AUTOSAR XML (schema 00049)
package /DataType/Implementation/CPP
  25 x std cpp implementation data type:
    AppVersion: category=ARRAY, array-size=6, cpp-template-argument=uint8_t
      namespaces:
        symbol props data
        symbol props table
    Color_Index: category=ARRAY, array-size=3, cpp-template-argument=uint8_t
      namespaces:
        symbol props data
        symbol props table
    Complete_Time: category=ARRAY, array-size=2, cpp-template-argument=uint8_t
      namespaces:
        symbol props data
        symbol props table
    Date: category=ARRAY, array-size=8, cpp-template-argument=uint8_t
      namespaces:
        symbol props data
        symbol props table
    Elapsed_Time: category=ARRAY, array-size=2, cpp-template-argument=uint8_t
      namespaces:
        symbol props data
        symbol props table
    Finished_Time: category=ARRAY, array-size=7, cpp-template-argument=uint8_t
      namespaces:
        symbol props data
        symbol props table
    InputData: category=STRUCTURE
      namespaces:
        symbol props bms
        symbol props input
      26 x cpp implementation data type element, all with type-reference=uint32_t:
        InterfaceIDforDbg
        DataSerialNumber
        VehicleUniqueSnr
        EMS_BatteryAvgTemperature
        EMS_ChargerOutputVolt
        EMS_ChargerOutputCurr
        EMS_ReturnCode
        EMS_ConnectionStatus
        EMS_TargetVolt
        EMS_TargetCurr
        EMS_RemainHour
        EMS_RemainMin
        EMS_HVBattSOC
        EMS_HVBattSOE
        EMS_HVBattSOH
        EMS_BattVolt
        EMS_BattCurr
        EMS_Obc_dcVolt
        EMS_Obc_dcCurr
        EMS_Avn_ChargeCurrSetSts
        EMS_HVBatt_MainRlyCloseReq
        EMS_HVBatt_preChrgRlyStatus
        EMS_HVBatt_posRlyStatus
        EMS_HVBatt_negRlyStatus
        EMS_Avn_DcChargingTargetSetSts
        EMS_Avn_AcChargingTargetSetSts
    MaxData: category=ARRAY, array-size=2, cpp-template-argument=uint8_t
      namespaces:
        symbol props data
        symbol props table
    MinData: category=ARRAY, array-size=2, cpp-template-argument=uint8_t
      namespaces:
        symbol props data
        symbol props table
    OutputData: category=STRUCTURE
      namespaces:
        symbol props bms
        symbol props output
      25 x cpp implementation data type element:
        InterfaceIDforDbg: type-reference=uint32_t
        VehicleUniqueSnr: type-reference=uint32_t
        AppVer: type-reference=AppVersion
        ChargeStatus: type-reference=uint8_t
        EMS_ConnectionStatus: type-reference=uint8_t
        Date: type-reference=Date
        BattSOC: type-reference=uint16_t
        DTE: type-reference=uint16_t
        BatteryStatus: type-reference=uint16_t
        SOH: type-reference=uint16_t
        SOE: type-reference=uint16_t
        TargetSOC: type-reference=uint8_t
        CompleteTime: type-reference=Complete_Time
        FinishedTime: type-reference=Finished_Time
        GetCount: type-reference=uint32_t
        MissedCount: type-reference=uint32_t
        ChargeResult: type-reference=uint16_t
        ChargedSOE: type-reference=uint16_t
        ChargedSOC: type-reference=uint16_t
        Current: type-reference=T_MSGINFO
        Voltage: type-reference=T_MSGINFO
        SOC: type-reference=T_MSGINFO
        Temp: type-reference=T_MSGINFO
        ElapsedTime: type-reference=Elapsed_Time
        ChargeStopReason: type-reference=uint32_t
    RCData: category=ARRAY, array-size=20, cpp-template-argument=uint8_t
      namespaces:
        symbol props data
        symbol props table
    SoaMImMoodeMode: compu {0=kCARE_MOOD, 1=kCOMPORT_MOOD, 2=kDELIGHT_MOOD, 3=kMOOD_THERAPY, 4=kVITALITY_MOOD}, type-reference=uint8_t
      namespaces:
        symbol props lmp
        symbol props mode
    T_MSGINFO: category=STRUCTURE
      namespaces:
        symbol props msg
        symbol props info
      8 x cpp implementation data type element:
        tRslt: type-reference=uint8_t
        XaxisScale: type-reference=uint8_t
        YaxisValidCnt: type-reference=uint8_t
        Ydata: type-reference=Y_Data
        RCValidCnt: type-reference=uint8_t
        RCdata: type-reference=RCData
        MAXdata: type-reference=MaxData
        MINdata: type-reference=MinData
    Y_Data: category=ARRAY, array-size=100, cpp-template-argument=uint8_t
      namespaces:
        symbol props data
        symbol props table
    bool: category=VALUE, type-emitter=FundamentalType
    double: category=VALUE, type-emitter=FundamentalType
    float: category=VALUE, type-emitter=FundamentalType
    int16_t: category=VALUE, header-file=cstdint
    int32_t: category=VALUE, header-file=cstdint
    int64_t: category=VALUE, header-file=cstdint
    int8_t: category=VALUE, header-file=cstdint
    uint16_t: category=VALUE, header-file=cstdint
    uint32_t: category=VALUE, header-file=cstdint
    uint64_t: category=VALUE, header-file=cstdint
    uint8_t: category=VALUE, header-file=cstdint
package /PortInterface/Service
  service interface BmsInfoSrv: major-version=1, minor-version=0
    namespaces:
      symbol props battery
      symbol props bmsinfo
    events:
      data ems_BmsInfo: type=InputData
  service interface EevpControlSoaMIm: major-version=1, minor-version=0
    namespaces:
      symbol props lmp
      symbol props control
    methods:
      operation RequestMImSetBrightness: fire-and-forget=false
        arg Brightness: type=uint16_t, direction=IN
      operation RequestMImSetMode: fire-and-forget=false
        arg mood: type=SoaMImMoodeMode, direction=IN
      operation RequestMImSetRGBColor: fire-and-forget=false
        arg ColorIndex: type=uint8_t, direction=IN
  service interface MsgInfoSrv: major-version=1, minor-version=0
    namespaces:
      symbol props batt
      symbol props msginfo
    events:
      data ems_MsgInfo: type=OutputData
package /System/Service/Deployment
  someip service interface deployment BmsInfoSrv: service-interface=BmsInfoSrv, service-interface-id=11, service-interface-version={major-version=1, minor-version=0}
    someip event deployment ems_BmsInfo: event=ems_BmsInfo, event-id=1, transport-protocol=UDP
    someip event group Eventgroup_ems_BmsInfo: event-group-id=1, event=ems_BmsInfo
  someip service interface deployment EevpControlSoaMIm: service-interface=EevpControlSoaMIm, service-interface-id=13, service-interface-version={major-version=1, minor-version=0}
    someip method deployment RequestMImSetBrightness: method=RequestMImSetBrightness, method-id=3, transport-protocol=UDP
    someip method deployment RequestMImSetMode: method=RequestMImSetMode, method-id=2, transport-protocol=UDP
    someip method deployment RequestMImSetRGBColor: method=RequestMImSetRGBColor, method-id=1, transport-protocol=UDP
  someip service interface deployment MsgInfoSrv: service-interface=MsgInfoSrv, service-interface-id=12, service-interface-version={major-version=1, minor-version=0}
    someip event deployment ems_MsgInfo: event=ems_MsgInfo, event-id=1, transport-protocol=UDP
    someip event group Eventgroup_ems_MsgInfo: event-group-id=1, event=ems_MsgInfo
package /System/Service/Endpoint
  6 x someip service instance to machine mapping, all with communication-connector=eth0:
    Consumer_BmsInfoSrv: service-instance=Consumer_BmsInfoSrv, tcp-port=10200, udp-port=10200
    Consumer_EevpControlSoaMIm: service-instance=Consumer_EevpControlSoaMIm, tcp-port=10600, udp-port=10600
    Consumer_MsgInfoSrv: service-instance=Consumer_MsgInfoSrv, tcp-port=10400, udp-port=10400
    Provider_BmsInfoSrv: service-instance=Provider_BmsInfoSrv, tcp-port=10100, udp-port=10100
    Provider_EevpControlSoaMIm: service-instance=Provider_EevpControlSoaMIm, tcp-port=10500, udp-port=10500
    Provider_MsgInfoSrv: service-instance=Provider_MsgInfoSrv, tcp-port=10300, udp-port=10300
package /System/Service/Instance
  required someip service instance Consumer_BmsInfoSrv: service-interface-deployment=BmsInfoSrv, required-minor-version=ANY, required-service-instance-id=ANY, sd-client-config=SdClientConfig
    someip required event group BmsInfoGr: event-group=BmsInfoGr, sd-client-event-group-timing-config=SdEventgroupConfig
  required someip service instance Consumer_EevpControlSoaMIm: service-interface-deployment=EevpControlSoaMIm, method-request-propss=[RequestMImSetRGBColor, RequestMImSetMode, RequestMImSetBrightness], required-minor-version=ANY, required-service-instance-id=ANY, sd-client-config=SdClientConfig
  required someip service instance Consumer_MsgInfoSrv: service-interface-deployment=MsgInfoSrv, required-minor-version=ANY, required-service-instance-id=ANY, sd-client-config=SdClientConfig
    someip required event group MsgInfoGr: event-group=MsgInfoGr, sd-client-event-group-timing-config=SdEventgroupConfig
  provided someip service instance Provider_BmsInfoSrv: service-interface-deployment=BmsInfoSrv, someip-event-props=ems_BmsInfo, sd-server-config=SdServerConfig, service-instance-id=1
    someip provided event group BmsInfoGr: event-group=BmsInfoGr, multicast-threshold=0
  provided someip service instance Provider_EevpControlSoaMIm: service-interface-deployment=EevpControlSoaMIm, method-response-propss=[RequestMImSetRGBColor, RequestMImSetMode, RequestMImSetBrightness], sd-server-config=SdServerConfig, service-instance-id=1
  provided someip service instance Provider_MsgInfoSrv: service-interface-deployment=MsgInfoSrv, someip-event-props=event=ems_MsgInfo, sd-server-config=SdServerConfig, service-instance-id=1
    someip provided event group MsgInfoGr: event-group=MsgInfoGr, multicast-threshold=0
package /System/Service/TimingConfig
  someip sd client service instance config SdClientConfig: initial-find-behavior={initial-delay-max-value=0.2, initial-delay-min-value=0.1, initial-repetitions-base-delay=0.1, initial-repetitions-max=4}, service-find-time-to-live=16777215
  someip sd client event group timing config SdEventgroupConfig: request-response-delay={max-value=0.0, min-value=0.0}, time-to-live=16777215
  someip sd server service instance config SdServerConfig: initial-offer-behavior={initial-delay-max-value=0.2, initial-delay-min-value=0.1, initial-repetitions-base-delay=0.1, initial-repetitions-max=3}, offer-cyclic-delay=0.5, request-response-delay={max-value=0.0, min-value=0.0}, service-offer-time-to-live=16777215
package /System/VehicleTopology/Cluster
  ethernet cluster EthernetCluster
    ethernet physical channel PhysicalChannel: category=WIRED, comm-connectors=eth0
      network endpoint EcuEndpoint: network-endpoint-addresses=ipv-4-configuration=ipv-4-address=127.0.0.1
      network endpoint SdEndpoint: network-endpoint-addresses=ipv-4-configuration=ipv-4-address=224.0.0.1
package /System/VehicleTopology/Ecu
  machine design Ecu: service-discover-configs=someip-service-discovery={multicast-sd-ip-address=SdEndpoint, someip-service-discovery-port=30490}
    user defined communication connector IPC
    ethernet communication connector eth0: unicast-network-endpoint=EcuEndpoint
package /AdaptiveApplication/DltConfig
  dlt log channel to process mapping DltLogChannelToProcessMapping_DltLogChannel_BatteryMonitor_TO_BatteryMonitor: dlt-log-channel=DltLogChannel_BatteryMonitor, process=BatteryMonitor
package /AdaptiveApplication/Executable
  executable BatteryMonitor: category=APPLICATION_LEVEL, logging-behavior=USES-LOGGING, reporting-behavior=REPORTS-EXECUTION-STATE, version=1.0.0
    root sw component prototype AA: application-type=BatteryMonitor
package /AdaptiveApplication/Manifest
  service instance to port prototype mapping BatteryMonitor_AA_P_MsgInfo: port-prototype=AA.P_MsgInfo, service-instance=Provider_MsgInfoSrv
  service instance to port prototype mapping BatteryMonitor_AA_R_BmsInfo: port-prototype=AA.R_BmsInfo, service-instance=Consumer_BmsInfoSrv
  service instance to port prototype mapping BatteryMonitor_AA_R_LmpCtrl: port-prototype=AA.R_LmpCtrl, service-instance=Consumer_EevpControlSoaMIm
package /AdaptiveApplication/Process
  process BatteryMonitor: executable=BatteryMonitor, state-dependent-startup-config{execution-dependency=CM.Running, function-group-state=MachineFG.Startup, resource-group=DefaultResourceGroup, startup-config=BatteryMonitor}
    process state machine BatteryMonitor: type=ProcessState
package /AdaptiveApplication/StartupConfig
  startup config set StartupConfigSet
    startup config BatteryMonitor: scheduling-policy=SCHED_OTHER, scheduling-priority=0
package /AdaptiveApplication/SwComponent
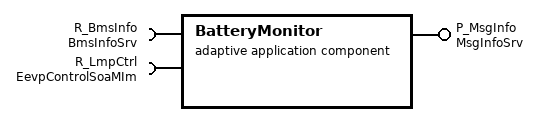
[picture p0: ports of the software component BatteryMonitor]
  adaptive application sw component type BatteryMonitor
    provide port P_MsgInfo: provided-interface=MsgInfoSrv
    require port R_BmsInfo: required-interface=BmsInfoSrv
    require port R_LmpCtrl: required-interface=EevpControlSoaMIm
